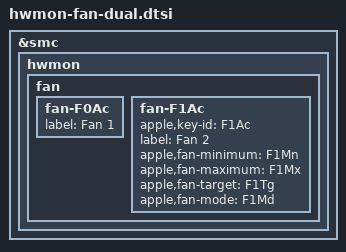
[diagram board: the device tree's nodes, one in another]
// SPDX-License-Identifier: GPL-2.0-or-later OR MIT
/*
 * SMC hwmon fan keys for Apple Silicon desktops/laptops with two fans
 *
 * Copyright The Asahi Linux Contributors
 */

#include "hwmon-fan.dtsi"

&smc {
	hwmon {
		fan{
			fan-F0Ac {
				label = "Fan 1";
			};

			fan-F1Ac {
				apple,key-id = "F1Ac";
				label = "Fan 2";
				apple,fan-minimum = "F1Mn";
				apple,fan-maximum = "F1Mx";
				apple,fan-target = "F1Tg";
				apple,fan-mode = "F1Md";
			};
		};
	};
};
